AUTOSAR XML (schema 00046)
package /ComponentTypes
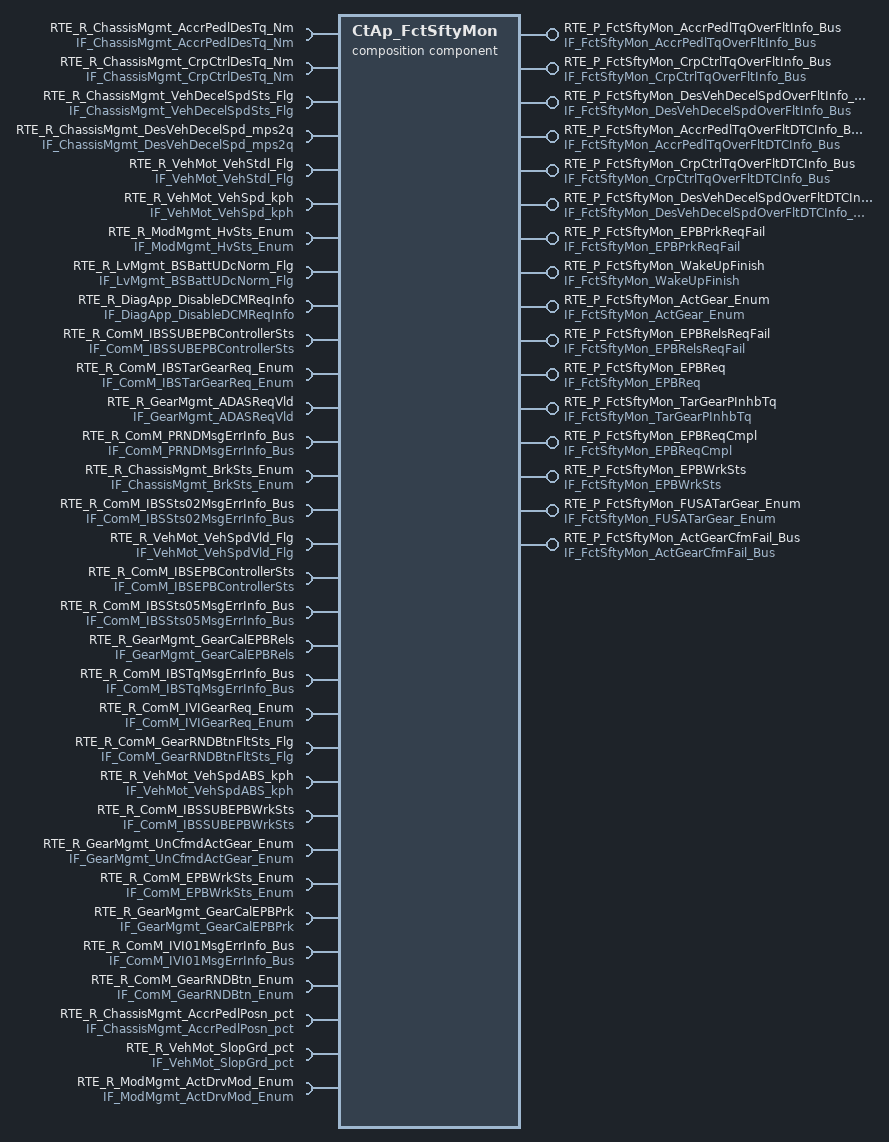
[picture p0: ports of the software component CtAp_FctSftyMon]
  composition sw component type CtAp_FctSftyMon
    provide port RTE_P_FctSftyMon_AccrPedlTqOverFltInfo_Bus: nonqueued-sender-com-spec{data-element=tec_FctSftyMon_AccrPedlTqOverFltInfo_Bus, init-value=fields=[FctSftyMon_MonStatAccrPedlTqOverFltInfo:0, FctSftyMon_MonResAccrPedlTqOverFltInfo:0, FctSftyMon_ErrStatAccrPedlTqOverFltInfo:0, FctSftyMon_ErrResAccrPedlTqOverFltInfo:0]}, provided-interface=IF_FctSftyMon_AccrPedlTqOverFltInfo_Bus
    provide port RTE_P_FctSftyMon_CrpCtrlTqOverFltInfo_Bus: nonqueued-sender-com-spec{data-element=tec_FctSftyMon_CrpCtrlTqOverFltInfo_Bus, init-value=fields=[FctSftyMon_MonStatCrpCtrlTqOverFltInfo:0, FctSftyMon_MonResCrpCtrlTqOverFltInfo:0, FctSftyMon_ErrStatCrpCtrlTqOverFltInfo:0, FctSftyMon_ErrResCrpCtrlTqOverFltInfo:0]}, provided-interface=IF_FctSftyMon_CrpCtrlTqOverFltInfo_Bus
    provide port RTE_P_FctSftyMon_DesVehDecelSpdOverFltInfo_Bus: nonqueued-sender-com-spec{data-element=tec_FctSftyMon_DesVehDecelSpdOverFltInfo_Bus, init-value=fields=[FctSftyMon_MonStatDesVehDecelSpdOverFltInfo:0, FctSftyMon_MonResDesVehDecelSpdOverFltInfo:0, FctSftyMon_ErrStatDesVehDecelSpdOverFltInfo:0, FctSftyMon_ErrResDesVehDecelSpdOverFltInfo:0]}, provided-interface=IF_FctSftyMon_DesVehDecelSpdOverFltInfo_Bus
    8 x require port:
      RTE_R_ChassisMgmt_AccrPedlDesTq_Nm: nonqueued-receiver-com-spec{data-element=tec_ChassisMgmt_AccrPedlDesTq_Nm, filter=data-filter-type=ALWAYS, init-value=0}, required-interface=IF_ChassisMgmt_AccrPedlDesTq_Nm
      RTE_R_ChassisMgmt_CrpCtrlDesTq_Nm: nonqueued-receiver-com-spec{data-element=tec_ChassisMgmt_CrpCtrlDesTq_Nm, filter=data-filter-type=ALWAYS, init-value=0}, required-interface=IF_ChassisMgmt_CrpCtrlDesTq_Nm
      RTE_R_ChassisMgmt_VehDecelSpdSts_Flg: nonqueued-receiver-com-spec{data-element=tec_ChassisMgmt_VehDecelSpdSts_Flg, filter=data-filter-type=ALWAYS, init-value=0}, required-interface=IF_ChassisMgmt_VehDecelSpdSts_Flg
      RTE_R_ChassisMgmt_DesVehDecelSpd_mps2q: nonqueued-receiver-com-spec{data-element=tec_ChassisMgmt_DesVehDecelSpd_mps2q, filter=data-filter-type=ALWAYS, init-value=0}, required-interface=IF_ChassisMgmt_DesVehDecelSpd_mps2q
      RTE_R_VehMot_VehStdl_Flg: nonqueued-receiver-com-spec{data-element=tec_VehMot_VehStdl_Flg, filter=data-filter-type=ALWAYS, init-value=0}, required-interface=IF_VehMot_VehStdl_Flg
      RTE_R_VehMot_VehSpd_kph: nonqueued-receiver-com-spec{data-element=tec_VehMot_VehSpd_kph, filter=data-filter-type=ALWAYS, init-value=0}, required-interface=IF_VehMot_VehSpd_kph
      RTE_R_ModMgmt_HvSts_Enum: nonqueued-receiver-com-spec{data-element=tec_ModMgmt_HvSts_Enum, filter=data-filter-type=ALWAYS, init-value=0}, required-interface=IF_ModMgmt_HvSts_Enum
      RTE_R_LvMgmt_BSBattUDcNorm_Flg: nonqueued-receiver-com-spec{data-element=tec_LvMgmt_BSBattUDcNorm_Flg, filter=data-filter-type=ALWAYS, init-value=0}, required-interface=IF_LvMgmt_BSBattUDcNorm_Flg
    provide port RTE_P_FctSftyMon_AccrPedlTqOverFltDTCInfo_Bus: nonqueued-sender-com-spec{data-element=tec_FctSftyMon_AccrPedlTqOverFltDTCInfo_Bus, init-value=fields=[FctSftyMon_MonStatAccrPedlTqOverFltInfo:0, FctSftyMon_MonResAccrPedlTqOverFltInfo:0, FctSftyMon_ErrStatAccrPedlTqOverFltInfo:0, FctSftyMon_ErrResAccrPedlTqOverFltInfo:0]}, provided-interface=IF_FctSftyMon_AccrPedlTqOverFltDTCInfo_Bus
    provide port RTE_P_FctSftyMon_CrpCtrlTqOverFltDTCInfo_Bus: nonqueued-sender-com-spec{data-element=tec_FctSftyMon_CrpCtrlTqOverFltDTCInfo_Bus, init-value=fields=[FctSftyMon_MonStatCrpCtrlTqOverFltInfo:0, FctSftyMon_MonResCrpCtrlTqOverFltInfo:0, FctSftyMon_ErrStatCrpCtrlTqOverFltInfo:0, FctSftyMon_ErrResCrpCtrlTqOverFltInfo:0]}, provided-interface=IF_FctSftyMon_CrpCtrlTqOverFltDTCInfo_Bus
    provide port RTE_P_FctSftyMon_DesVehDecelSpdOverFltDTCInfo_Bus: nonqueued-sender-com-spec{data-element=tec_FctSftyMon_DesVehDecelSpdOverFltDTCInfo_Bus, init-value=fields=[FctSftyMon_MonStatDesVehDecelSpdOverFltInfo:0, FctSftyMon_MonResDesVehDecelSpdOverFltInfo:0, FctSftyMon_ErrStatDesVehDecelSpdOverFltInfo:0, FctSftyMon_ErrResDesVehDecelSpdOverFltInfo:0]}, provided-interface=IF_FctSftyMon_DesVehDecelSpdOverFltDTCInfo_Bus
    require port RTE_R_DiagApp_DisableDCMReqInfo: nonqueued-receiver-com-spec{data-element=tec_DiagApp_DisableDCMReqInfo, filter=data-filter-type=ALWAYS, init-value=0}, required-interface=IF_DiagApp_DisableDCMReqInfo
    10 x provide port:
      RTE_P_FctSftyMon_EPBPrkReqFail: nonqueued-sender-com-spec{data-element=tec_FctSftyMon_EPBPrkReqFail, init-value=0}, provided-interface=IF_FctSftyMon_EPBPrkReqFail
      RTE_P_FctSftyMon_WakeUpFinish: nonqueued-sender-com-spec{data-element=tec_FctSftyMon_WakeUpFinish, init-value=0}, provided-interface=IF_FctSftyMon_WakeUpFinish
      RTE_P_FctSftyMon_ActGear_Enum: nonqueued-sender-com-spec{data-element=tec_FctSftyMon_ActGear_Enum, init-value=0}, provided-interface=IF_FctSftyMon_ActGear_Enum
      RTE_P_FctSftyMon_EPBRelsReqFail: nonqueued-sender-com-spec{data-element=tec_FctSftyMon_EPBRelsReqFail, init-value=0}, provided-interface=IF_FctSftyMon_EPBRelsReqFail
      RTE_P_FctSftyMon_EPBReq: nonqueued-sender-com-spec{data-element=tec_FctSftyMon_EPBReq, init-value=0}, provided-interface=IF_FctSftyMon_EPBReq
      RTE_P_FctSftyMon_TarGearPInhbTq: nonqueued-sender-com-spec{data-element=tec_FctSftyMon_TarGearPInhbTq, init-value=0}, provided-interface=IF_FctSftyMon_TarGearPInhbTq
      RTE_P_FctSftyMon_EPBReqCmpl: nonqueued-sender-com-spec{data-element=tec_FctSftyMon_EPBReqCmpl, init-value=0}, provided-interface=IF_FctSftyMon_EPBReqCmpl
      RTE_P_FctSftyMon_EPBWrkSts: nonqueued-sender-com-spec{data-element=tec_FctSftyMon_EPBWrkSts, init-value=0}, provided-interface=IF_FctSftyMon_EPBWrkSts
      RTE_P_FctSftyMon_FUSATarGear_Enum: nonqueued-sender-com-spec{data-element=tec_FctSftyMon_FUSATarGear_Enum, init-value=0}, provided-interface=IF_FctSftyMon_FUSATarGear_Enum
      RTE_P_FctSftyMon_ActGearCfmFail_Bus: nonqueued-sender-com-spec{data-element=tec_FctSftyMon_ActGearCfmFail_Bus, init-value=fields=[FctSftyMon_MonStatActGearCfmFail:0, FctSftyMon_MonResActGearCfmFail:0, FctSftyMon_ErrStatActGearCfmFail:0, FctSftyMon_ErrResActGearCfmFail:0]}, provided-interface=IF_FctSftyMon_ActGearCfmFail_Bus
    provide/require port RTE_RP_GearMgmtInfo: nv-provide-com-spec{ram-block-init-value=fields=[GearMgmt_GearMemInfo_Enum:0, GearMgmt_FillAddress:0], rom-block-init-value=fields=[GearMgmt_GearMemInfo_Enum:0, GearMgmt_FillAddress:0], variable=tec_GearMgmtInfo}, nv-require-com-spec{init-value=fields=[GearMgmt_GearMemInfo_Enum:0, GearMgmt_FillAddress:0], variable=tec_GearMgmtInfo}, provided-required-interface=IF_GearMgmtInfo
    23 x require port:
      RTE_R_ComM_IBSSUBEPBControllerSts: nonqueued-receiver-com-spec{data-element=tec_ComM_IBSSUBEPBControllerSts, filter=data-filter-type=ALWAYS, init-value=0}, required-interface=IF_ComM_IBSSUBEPBControllerSts
      RTE_R_ComM_IBSTarGearReq_Enum: nonqueued-receiver-com-spec{data-element=tec_ComM_IBSTarGearReq_Enum, filter=data-filter-type=ALWAYS, init-value=0}, required-interface=IF_ComM_IBSTarGearReq_Enum
      RTE_R_GearMgmt_ADASReqVld: nonqueued-receiver-com-spec{data-element=tec_GearMgmt_ADASReqVld, filter=data-filter-type=ALWAYS, init-value=0}, required-interface=IF_GearMgmt_ADASReqVld
      RTE_R_ComM_PRNDMsgErrInfo_Bus: required-interface=IF_ComM_PRNDMsgErrInfo_Bus
        required-com-specs:
          data-element=tec_ComM_PRNDTimeoutInfo_Bus, filter=data-filter-type=ALWAYS, init-value=fields=[ComM_MonStatPRNDTimeoutInfo:0, ComM_MonResPRNDTimeoutInfo:0, ComM_ErrStatPRNDTimeoutInfo:0, ComM_ErrResPRNDTimeoutInfo:0]
          data-element=tec_ComM_PRNDCRCDTCInfo_Bus, filter=data-filter-type=ALWAYS, init-value=fields=[ComM_MonStatPRNDCRCDTCErrorInfo:0, ComM_MonResPRNDCRCDTCErrorInfo:0, ComM_ErrStatPRNDCRCDTCErrorInfo:0, ComM_ErrResPRNDCRCDTCErrorInfo:0]
          data-element=tec_ComM_PRNDCRCInfo_Bus, filter=data-filter-type=ALWAYS, init-value=fields=[ComM_MonStatPRNDCRCErrorInfo:0, ComM_MonResPRNDCRCErrorInfo:0, ComM_ErrStatPRNDCRCErrorInfo:0, ComM_ErrResPRNDCRCErrorInfo:0]
          data-element=tec_ComM_PRNDTimeoutDTCInfo_Bus, filter=data-filter-type=ALWAYS, init-value=fields=[ComM_MonStatPRNDTimeoutDTCErrorInfo:0, ComM_MonResPRNDTimeoutDTCErrorInfo:0, ComM_ErrStatPRNDTimeoutDTCErrorInfo:0, ComM_ErrResPRNDTimeoutDTCErrorInfo:0]
          data-element=tec_ComM_PRNDE2ETimeoutInfo_Bus, filter=data-filter-type=ALWAYS, init-value=fields=[ComM_MonStatPRNDE2ETimeoutInfo:0, ComM_MonResPRNDE2ETimeoutInfo:0, ComM_ErrStatPRNDE2ETimeoutInfo:0, ComM_ErrResPRNDE2ETimeoutInfo:0]
      RTE_R_ChassisMgmt_BrkSts_Enum: nonqueued-receiver-com-spec{data-element=tec_ChassisMgmt_BrkSts_Enum, filter=data-filter-type=ALWAYS, init-value=0}, required-interface=IF_ChassisMgmt_BrkSts_Enum
      RTE_R_ComM_IBSSts02MsgErrInfo_Bus: required-interface=IF_ComM_IBSSts02MsgErrInfo_Bus
        required-com-specs:
          data-element=tec_ComM_IBSSts02CRCInfo_Bus, filter=data-filter-type=ALWAYS, init-value=fields=[ComM_MonStatIBSSts02CRCErrorInfo:0, ComM_MonResIBSSts02CRCErrorInfo:0, ComM_ErrStatIBSSts02CRCErrorInfo:0, ComM_ErrResIBSSts02CRCErrorInfo:0]
          data-element=tec_ComM_IBSSts02CRCDTCInfo_Bus, filter=data-filter-type=ALWAYS, init-value=fields=[ComM_MonStatIBSSts02CRCDTCErrorInfo:0, ComM_MonResIBSSts02CRCDTCErrorInfo:0, ComM_ErrStatIBSSts02CRCDTCErrorInfo:0, ComM_ErrResIBSSts02CRCDTCErrorInfo:0]
          data-element=tec_ComM_IBSSts02TimeoutDTCInfo_Bus, filter=data-filter-type=ALWAYS, init-value=fields=[ComM_MonStatIBSSts02TimeoutDTCErrorInfo:0, ComM_MonResIBSSts02TimeoutDTCErrorInfo:0, ComM_ErrStatIBSSts02TimeoutDTCErrorInfo:0, ComM_ErrResIBSSts02TimeoutDTCErrorInfo:0]
          data-element=tec_ComM_IBSSts02E2ETimeoutInfo_Bus, filter=data-filter-type=ALWAYS, init-value=fields=[ComM_MonStatIBSSts02E2ETimeoutInfo:0, ComM_MonResIBSSts02E2ETimeoutInfo:0, ComM_ErrStatIBSSts02E2ETimeoutInfo:0, ComM_ErrResIBSSts02E2ETimeoutInfo:0]
      RTE_R_VehMot_VehSpdVld_Flg: nonqueued-receiver-com-spec{data-element=tec_VehMot_VehSpdVld_Flg, filter=data-filter-type=ALWAYS, init-value=0}, required-interface=IF_VehMot_VehSpdVld_Flg
      RTE_R_ComM_IBSEPBControllerSts: nonqueued-receiver-com-spec{data-element=tec_ComM_IBSEPBControllerSts, filter=data-filter-type=ALWAYS, init-value=0}, required-interface=IF_ComM_IBSEPBControllerSts
      RTE_R_ComM_IBSSts05MsgErrInfo_Bus: required-interface=IF_ComM_IBSSts05MsgErrInfo_Bus
        required-com-specs:
          data-element=tec_ComM_IBSSts05CRCDTCInfo_Bus, filter=data-filter-type=ALWAYS, init-value=fields=[ComM_MonStatIBSSts05CRCDTCErrorInfo:0, ComM_MonResIBSSts05CRCDTCErrorInfo:0, ComM_ErrStatIBSSts05CRCDTCErrorInfo:0, ComM_ErrResIBSSts05CRCDTCErrorInfo:0]
          data-element=tec_ComM_IBSSts05TimeoutDTCInfo_Bus, filter=data-filter-type=ALWAYS, init-value=fields=[ComM_MonStatIBSSts05TimeoutDTCErrorInfo:0, ComM_MonResIBSSts05TimeoutDTCErrorInfo:0, ComM_ErrStatIBSSts05TimeoutDTCErrorInfo:0, ComM_ErrResIBSSts05TimeoutDTCErrorInfo:0]
          data-element=tec_ComM_IBSSts05TimeoutInfo_Bus, filter=data-filter-type=ALWAYS, init-value=fields=[ComM_MonStatIBSSts05TimeoutInfo:0, ComM_MonResIBSSts05TimeoutInfo:0, ComM_ErrStatIBSSts05TimeoutInfo:0, ComM_ErrResIBSSts05TimeoutInfo:0]
          data-element=tec_ComM_IBSSts05CRCInfo_Bus, filter=data-filter-type=ALWAYS, init-value=fields=[ComM_MonStatIBSSts05CRCErrorInfo:0, ComM_MonResIBSSts05CRCErrorInfo:0, ComM_ErrStatIBSSts05CRCErrorInfo:0, ComM_ErrResIBSSts05CRCErrorInfo:0]
          data-element=tec_ComM_IBSSts05E2ETimeoutInfo_Bus, filter=data-filter-type=ALWAYS, init-value=fields=[ComM_MonStatIBSSts05E2ETimeoutInfo:0, ComM_MonResIBSSts05E2ETimeoutInfo:0, ComM_ErrStatIBSSts05E2ETimeoutInfo:0, ComM_ErrResIBSSts05E2ETimeoutInfo:0]
      RTE_R_GearMgmt_GearCalEPBRels: nonqueued-receiver-com-spec{data-element=tec_GearMgmt_GearCalEPBRels, filter=data-filter-type=ALWAYS, init-value=0}, required-interface=IF_GearMgmt_GearCalEPBRels
      RTE_R_ComM_IBSTqMsgErrInfo_Bus: required-interface=IF_ComM_IBSTqMsgErrInfo_Bus
        required-com-specs:
          data-element=tec_ComM_IBSTqCRCDTCInfo_Bus, filter=data-filter-type=ALWAYS, init-value=fields=[ComM_MonStatIBSTqCRCDTCErrorInfo:0, ComM_MonResIBSTqCRCDTCErrorInfo:0, ComM_ErrStatIBSTqCRCDTCErrorInfo:0, ComM_ErrResIBSTqCRCDTCErrorInfo:0]
          data-element=tec_ComM_IBSTqTimeoutDTCInfo_Bus, filter=data-filter-type=ALWAYS, init-value=fields=[ComM_MonStatIBSTqTimeoutDTCErrorInfo:0, ComM_MonResIBSTqTimeoutDTCErrorInfo:0, ComM_ErrStatIBSTqTimeoutDTCErrorInfo:0, ComM_ErrResIBSTqTimeoutDTCErrorInfo:0]
          data-element=tec_ComM_IBSTqCRCInfo_Bus, filter=data-filter-type=ALWAYS, init-value=fields=[ComM_MonStatIBSTqCRCErrorInfo:0, ComM_MonResIBSTqCRCErrorInfo:0, ComM_ErrStatIBSTqCRCErrorInfo:0, ComM_ErrResIBSTqCRCErrorInfo:0]
          data-element=tec_ComM_IBSTqE2ETimeoutInfo_Bus, filter=data-filter-type=ALWAYS, init-value=fields=[ComM_MonStatIBSTqE2ETimeoutInfo:0, ComM_MonResIBSTqE2ETimeoutInfo:0, ComM_ErrStatIBSTqE2ETimeoutInfo:0, ComM_ErrResIBSTqE2ETimeoutInfo:0]
      RTE_R_ComM_IVIGearReq_Enum: nonqueued-receiver-com-spec{data-element=tec_ComM_IVIGearReq_Enum, filter=data-filter-type=ALWAYS, init-value=0}, required-interface=IF_ComM_IVIGearReq_Enum
      RTE_R_ComM_GearRNDBtnFltSts_Flg: nonqueued-receiver-com-spec{data-element=tec_ComM_GearRNDBtnFltSts_Flg, filter=data-filter-type=ALWAYS, init-value=0}, required-interface=IF_ComM_GearRNDBtnFltSts_Flg
      RTE_R_VehMot_VehSpdABS_kph: nonqueued-receiver-com-spec{data-element=tec_VehMot_VehSpdABS_kph, filter=data-filter-type=ALWAYS, init-value=0}, required-interface=IF_VehMot_VehSpdABS_kph
      RTE_R_ComM_IBSSUBEPBWrkSts: nonqueued-receiver-com-spec{data-element=tec_ComM_IBSSUBEPBWrkSts, filter=data-filter-type=ALWAYS, init-value=0}, required-interface=IF_ComM_IBSSUBEPBWrkSts
      RTE_R_GearMgmt_UnCfmdActGear_Enum: nonqueued-receiver-com-spec{data-element=tec_GearMgmt_UnCfmdActGear_Enum, filter=data-filter-type=ALWAYS, init-value=0}, required-interface=IF_GearMgmt_UnCfmdActGear_Enum
      RTE_R_ComM_EPBWrkSts_Enum: nonqueued-receiver-com-spec{data-element=tec_ComM_EPBWrkSts_Enum, filter=data-filter-type=ALWAYS, init-value=0}, required-interface=IF_ComM_EPBWrkSts_Enum
      RTE_R_GearMgmt_GearCalEPBPrk: nonqueued-receiver-com-spec{data-element=tec_GearMgmt_GearCalEPBPrk, filter=data-filter-type=ALWAYS, init-value=0}, required-interface=IF_GearMgmt_GearCalEPBPrk
      RTE_R_ComM_IVI01MsgErrInfo_Bus: required-interface=IF_ComM_IVI01MsgErrInfo_Bus
        required-com-specs:
          data-element=tec_ComM_IVI01CRCInfo_Bus, filter=data-filter-type=ALWAYS, init-value=fields=[ComM_MonStatIVI01CRCErrorInfo:0, ComM_MonResIVI01CRCErrorInfo:0, ComM_ErrStatIVI01CRCErrorInfo:0, ComM_ErrResIVI01CRCErrorInfo:0]
          data-element=tec_ComM_IVI01E2ETimeoutInfo_Bus, filter=data-filter-type=ALWAYS, init-value=fields=[ComM_MonStatIVI01E2ETimeoutInfo:0, ComM_MonResIVI01E2ETimeoutInfo:0, ComM_ErrStatIVI01E2ETimeoutInfo:0, ComM_ErrResIVI01E2ETimeoutInfo:0]
      RTE_R_ComM_GearRNDBtn_Enum: nonqueued-receiver-com-spec{data-element=tec_ComM_GearRNDBtn_Enum, filter=data-filter-type=ALWAYS, init-value=0}, required-interface=IF_ComM_GearRNDBtn_Enum
      RTE_R_ChassisMgmt_AccrPedlPosn_pct: nonqueued-receiver-com-spec{data-element=tec_ChassisMgmt_AccrPedlPosn_pct, filter=data-filter-type=ALWAYS, init-value=0}, required-interface=IF_ChassisMgmt_AccrPedlPosn_pct
      RTE_R_VehMot_SlopGrd_pct: nonqueued-receiver-com-spec{data-element=tec_VehMot_SlopGrd_pct, filter=data-filter-type=ALWAYS}, required-interface=IF_VehMot_SlopGrd_pct
      RTE_R_ModMgmt_ActDrvMod_Enum: nonqueued-receiver-com-spec{data-element=tec_ModMgmt_ActDrvMod_Enum, filter=data-filter-type=ALWAYS, init-value=0}, required-interface=IF_ModMgmt_ActDrvMod_Enum
    component CtAp_FctSftyGear: type=CtAp_FctSftyGear
    component CtAp_FctSftyTorq: type=CtAp_FctSftyTorq
    delegate CtAp_FctSftyTorq.RTE_R_ChassisMgmt_DesVehDecelSpd_mps2q <-> outer port RTE_R_ChassisMgmt_DesVehDecelSpd_mps2q
    delegate CtAp_FctSftyTorq.RTE_R_ChassisMgmt_VehDecelSpdSts_Flg <-> outer port RTE_R_ChassisMgmt_VehDecelSpdSts_Flg
    delegate CtAp_FctSftyTorq.RTE_R_ChassisMgmt_AccrPedlDesTq_Nm <-> outer port RTE_R_ChassisMgmt_AccrPedlDesTq_Nm
    delegate CtAp_FctSftyTorq.RTE_R_ModMgmt_HvSts_Enum <-> outer port RTE_R_ModMgmt_HvSts_Enum
    delegate CtAp_FctSftyTorq.RTE_R_VehMot_VehStdl_Flg <-> outer port RTE_R_VehMot_VehStdl_Flg
    delegate CtAp_FctSftyTorq.RTE_R_ChassisMgmt_CrpCtrlDesTq_Nm <-> outer port RTE_R_ChassisMgmt_CrpCtrlDesTq_Nm
    delegate CtAp_FctSftyTorq.RTE_R_VehMot_VehSpd_kph <-> outer port RTE_R_VehMot_VehSpd_kph
    delegate CtAp_FctSftyTorq.RTE_P_FctSftyMon_DesVehDecelSpdOverFltInfo_Bus <-> outer port RTE_P_FctSftyMon_DesVehDecelSpdOverFltInfo_Bus
    delegate CtAp_FctSftyTorq.RTE_P_FctSftyMon_CrpCtrlTqOverFltInfo_Bus <-> outer port RTE_P_FctSftyMon_CrpCtrlTqOverFltInfo_Bus
    delegate CtAp_FctSftyTorq.RTE_P_FctSftyMon_AccrPedlTqOverFltInfo_Bus <-> outer port RTE_P_FctSftyMon_AccrPedlTqOverFltInfo_Bus
    delegate CtAp_FctSftyTorq.RTE_R_LvMgmt_BSBattUDcNorm_Flg <-> outer port RTE_R_LvMgmt_BSBattUDcNorm_Flg
    delegate CtAp_FctSftyTorq.RTE_P_FctSftyMon_AccrPedlTqOverFltDTCInfo_Bus <-> outer port RTE_P_FctSftyMon_AccrPedlTqOverFltDTCInfo_Bus
    delegate CtAp_FctSftyTorq.RTE_P_FctSftyMon_CrpCtrlTqOverFltDTCInfo_Bus <-> outer port RTE_P_FctSftyMon_CrpCtrlTqOverFltDTCInfo_Bus
    delegate CtAp_FctSftyTorq.RTE_P_FctSftyMon_DesVehDecelSpdOverFltDTCInfo_Bus <-> outer port RTE_P_FctSftyMon_DesVehDecelSpdOverFltDTCInfo_Bus
    delegate CtAp_FctSftyTorq.RTE_R_DiagApp_DisableDCMReqInfo <-> outer port RTE_R_DiagApp_DisableDCMReqInfo
    delegate CtAp_FctSftyGear.RTE_P_FctSftyMon_EPBPrkReqFail <-> outer port RTE_P_FctSftyMon_EPBPrkReqFail
    delegate CtAp_FctSftyGear.RTE_P_FctSftyMon_WakeUpFinish <-> outer port RTE_P_FctSftyMon_WakeUpFinish
    delegate CtAp_FctSftyGear.RTE_P_FctSftyMon_ActGear_Enum <-> outer port RTE_P_FctSftyMon_ActGear_Enum
    delegate CtAp_FctSftyGear.RTE_P_FctSftyMon_EPBRelsReqFail <-> outer port RTE_P_FctSftyMon_EPBRelsReqFail
    delegate CtAp_FctSftyGear.RTE_P_FctSftyMon_EPBReq <-> outer port RTE_P_FctSftyMon_EPBReq
    delegate CtAp_FctSftyGear.RTE_P_FctSftyMon_TarGearPInhbTq <-> outer port RTE_P_FctSftyMon_TarGearPInhbTq
    delegate CtAp_FctSftyGear.RTE_P_FctSftyMon_EPBReqCmpl <-> outer port RTE_P_FctSftyMon_EPBReqCmpl
    delegate CtAp_FctSftyGear.RTE_P_FctSftyMon_EPBWrkSts <-> outer port RTE_P_FctSftyMon_EPBWrkSts
    delegate CtAp_FctSftyGear.RTE_P_FctSftyMon_FUSATarGear_Enum <-> outer port RTE_P_FctSftyMon_FUSATarGear_Enum
    delegate CtAp_FctSftyGear.RTE_P_FctSftyMon_ActGearCfmFail_Bus <-> outer port RTE_P_FctSftyMon_ActGearCfmFail_Bus
    delegate CtAp_FctSftyGear.RTE_RP_GearMgmtInfo <-> outer port RTE_RP_GearMgmtInfo
    delegate CtAp_FctSftyGear.RTE_R_ComM_IBSSUBEPBControllerSts <-> outer port RTE_R_ComM_IBSSUBEPBControllerSts
    delegate CtAp_FctSftyGear.RTE_R_ComM_IBSTarGearReq_Enum <-> outer port RTE_R_ComM_IBSTarGearReq_Enum
    delegate CtAp_FctSftyGear.RTE_R_GearMgmt_ADASReqVld <-> outer port RTE_R_GearMgmt_ADASReqVld
    delegate CtAp_FctSftyGear.RTE_R_ComM_PRNDMsgErrInfo_Bus <-> outer port RTE_R_ComM_PRNDMsgErrInfo_Bus
    delegate CtAp_FctSftyGear.RTE_R_ChassisMgmt_BrkSts_Enum <-> outer port RTE_R_ChassisMgmt_BrkSts_Enum
    delegate CtAp_FctSftyGear.RTE_R_ComM_IBSSts02MsgErrInfo_Bus <-> outer port RTE_R_ComM_IBSSts02MsgErrInfo_Bus
    delegate CtAp_FctSftyGear.RTE_R_VehMot_VehSpdVld_Flg <-> outer port RTE_R_VehMot_VehSpdVld_Flg
    delegate CtAp_FctSftyGear.RTE_R_ComM_IBSEPBControllerSts <-> outer port RTE_R_ComM_IBSEPBControllerSts
    delegate CtAp_FctSftyGear.RTE_R_ComM_IBSSts05MsgErrInfo_Bus <-> outer port RTE_R_ComM_IBSSts05MsgErrInfo_Bus
    delegate CtAp_FctSftyGear.RTE_R_GearMgmt_GearCalEPBRels <-> outer port RTE_R_GearMgmt_GearCalEPBRels
    delegate CtAp_FctSftyGear.RTE_R_ComM_IBSTqMsgErrInfo_Bus <-> outer port RTE_R_ComM_IBSTqMsgErrInfo_Bus
    delegate CtAp_FctSftyGear.RTE_R_ComM_IVIGearReq_Enum <-> outer port RTE_R_ComM_IVIGearReq_Enum
    delegate CtAp_FctSftyGear.RTE_R_ComM_GearRNDBtnFltSts_Flg <-> outer port RTE_R_ComM_GearRNDBtnFltSts_Flg
    delegate CtAp_FctSftyGear.RTE_R_VehMot_VehSpdABS_kph <-> outer port RTE_R_VehMot_VehSpdABS_kph
    delegate CtAp_FctSftyGear.RTE_R_ComM_IBSSUBEPBWrkSts <-> outer port RTE_R_ComM_IBSSUBEPBWrkSts
    delegate CtAp_FctSftyGear.RTE_R_GearMgmt_UnCfmdActGear_Enum <-> outer port RTE_R_GearMgmt_UnCfmdActGear_Enum
    delegate CtAp_FctSftyGear.RTE_R_ComM_EPBWrkSts_Enum <-> outer port RTE_R_ComM_EPBWrkSts_Enum
    delegate CtAp_FctSftyGear.RTE_R_GearMgmt_GearCalEPBPrk <-> outer port RTE_R_GearMgmt_GearCalEPBPrk
    delegate CtAp_FctSftyGear.RTE_R_ComM_IVI01MsgErrInfo_Bus <-> outer port RTE_R_ComM_IVI01MsgErrInfo_Bus
    delegate CtAp_FctSftyGear.RTE_R_ComM_GearRNDBtn_Enum <-> outer port RTE_R_ComM_GearRNDBtn_Enum
    connect CtAp_FctSftyGear.RTE_P_FctSftyMon_ActGear_Enum -> CtAp_FctSftyTorq.RTE_R_FctSftyMon_ActGear_Enum
    delegate CtAp_FctSftyGear.RTE_R_DiagApp_DisableDCMReqInfo <-> outer port RTE_R_DiagApp_DisableDCMReqInfo
    delegate CtAp_FctSftyGear.RTE_R_VehMot_VehStdl_Flg <-> outer port RTE_R_VehMot_VehStdl_Flg
    delegate CtAp_FctSftyGear.RTE_R_LvMgmt_BSBattUDcNorm_Flg <-> outer port RTE_R_LvMgmt_BSBattUDcNorm_Flg
    delegate CtAp_FctSftyTorq.RTE_R_ChassisMgmt_AccrPedlPosn_pct <-> outer port RTE_R_ChassisMgmt_AccrPedlPosn_pct
    delegate CtAp_FctSftyTorq.RTE_R_VehMot_SlopGrd_pct <-> outer port RTE_R_VehMot_SlopGrd_pct
    delegate CtAp_FctSftyTorq.RTE_R_ModMgmt_ActDrvMod_Enum <-> outer port RTE_R_ModMgmt_ActDrvMod_Enum
